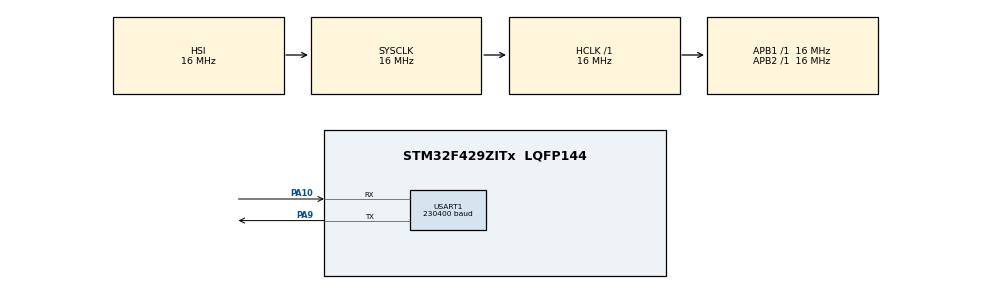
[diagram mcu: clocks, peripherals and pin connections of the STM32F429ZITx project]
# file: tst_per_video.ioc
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Mcu.Family=STM32F4
Mcu.Name=STM32F429ZITx
Mcu.Package=LQFP144
NVIC.PriorityGroup=NVIC_PRIORITYGROUP_4
NVIC.TIM1_UP_TIM10_IRQn=true\:0\:0\:false\:false\:true\:false\:true
NVIC.TimeBase=TIM1_UP_TIM10_IRQn
NVIC.TimeBaseIP=TIM1
PA10.Mode=Asynchronous
PA10.Signal=USART1_RX
PA13.Mode=Serial_Wire
PA13.Signal=SYS_JTMS-SWDIO
PA14.Mode=Serial_Wire
PA14.Signal=SYS_JTCK-SWCLK
PA9.Mode=Asynchronous
PA9.Signal=USART1_TX
PH0/OSC_IN.Mode=HSE-External-Oscillator
PH0/OSC_IN.Signal=RCC_OSC_IN
PH1/OSC_OUT.Mode=HSE-External-Oscillator
PH1/OSC_OUT.Signal=RCC_OSC_OUT
ProjectManager.HeapSize=0x200
ProjectManager.StackSize=0x400
ProjectManager.TargetToolchain=STM32CubeIDE
RCC.AHBFreq_Value=16000000
RCC.APB1Freq_Value=16000000
RCC.APB2Freq_Value=16000000
RCC.CortexFreq_Value=16000000
RCC.HSE_VALUE=25000000
RCC.HSI_VALUE=16000000
RCC.LSE_VALUE=32768
RCC.SYSCLKFreq_VALUE=16000000
RCC.VCOOutputFreq_Value=192000000
USART1.BaudRate=230400
USART1.VirtualMode=VM_ASYNC
VP_SYS_VS_tim1.Mode=TIM1
board=custom

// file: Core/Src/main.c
/* USER CODE BEGIN Header */
/**
 ******************************************************************************
 * @file           : main.c
 * @brief          : Main program body
 ******************************************************************************
 * @attention
 *
 * <h2><center>&copy; Copyright (c) 2020 STMicroelectronics.
 * All rights reserved.</center></h2>
 *
 * This software component is licensed by ST under BSD 3-Clause license,
 * the "License"; You may not use this file except in compliance with the
 * License. You may obtain a copy of the License at:
 *                        opensource.org/licenses/BSD-3-Clause
 *
 ******************************************************************************
 */
/* USER CODE END Header */

#define ARM_MATH_CM4

#include "main.h"
#include "arm_math.h"
#include "coefficients.h"

/* USER CODE BEGIN PD */
#define BUFFERSIZE	320
#define FILTERORDER 256
/* USER CODE END PD */

UART_HandleTypeDef huart1;

/* USER CODE BEGIN PV */
uint8_t txBuffer[BUFFERSIZE];

float32_t f_tempBuffer[BUFFERSIZE];
float32_t f_tempBuffer_out[BUFFERSIZE];

float32_t f_states[FILTERORDER];

q15_t temp_q15_Buffer[BUFFERSIZE];

typedef union{
	int16_t smp;
	uint8_t bytes[2];
} sample;

sample rxBuffer[BUFFERSIZE]; //Buffer de muestras

arm_fir_instance_f32 fir_0;
/* USER CODE END PV */

void SystemClock_Config(void);
static void MX_GPIO_Init(void);
static void MX_USART1_UART_Init(void);

int main(void)
{
	/* USER CODE BEGIN 1 */
	uint8_t data[]="1111";
	uint8_t rxdata[2];
	uint8_t txdata[2];

	int i;

	float32_t * currentCoef = left[0];

	arm_fir_init_f32(&fir_0, 256, currentCoef, f_states, BUFFERSIZE);
	/* USER CODE END 1 */

	/* MCU Configuration--------------------------------------------------------*/

	/* Reset of all peripherals, Initializes the Flash interface and the Systick. */
	HAL_Init();

	/* Configure the system clock */
	SystemClock_Config();

	/* Initialize all configured peripherals */
	MX_GPIO_Init();
	MX_USART1_UART_Init();

	/* Infinite loop */
	while (1)
	{

		/* USER CODE BEGIN 3 */
		HAL_UART_Receive(&huart1, rxBuffer->bytes, BUFFERSIZE*2, 10000);

		// Type changing
//		for(i=0;i<BUFFERSIZE;i++) {
//			temp_q15_Buffer[i*2+1]=(uint8_t)rxBuffer[i]&0xFF;
//			temp_q15_Buffer[i*2]=(uint8_t)rxBuffer[i]>>8;
//		}

		for (i = 0; i < BUFFERSIZE; i++) {
			f_tempBuffer[i] = (float32_t) rxBuffer[i].smp / 32768;
		}

		for (i = 0; i < 37; i++) {
			currentCoef = left[i];
//			arm_fir_f32(&fir_0, f_tempBuffer, f_tempBuffer_out, BUFFERSIZE);
		}

//		arm_q15_to_float(temp_q15_Buffer, f_tempBuffer, BUFFERSIZE);

		// Copy the data to the transmisor buffer
//		for (i = 0; i < 2; i++) {
//			txdata[i]=rxdata[i];
//		}

		i=0;

//		HAL_UART_Transmit(&huart1, txdata, 5, 1000);

	}
	/* USER CODE END 3 */
}

void SystemClock_Config(void)
{
	RCC_OscInitTypeDef RCC_OscInitStruct = {0};
	RCC_ClkInitTypeDef RCC_ClkInitStruct = {0};

	/** Configure the main internal regulator output voltage
	 */
	__HAL_RCC_PWR_CLK_ENABLE();
	__HAL_PWR_VOLTAGESCALING_CONFIG(PWR_REGULATOR_VOLTAGE_SCALE3);
	/** Initializes the CPU, AHB and APB busses clocks
	 */
	RCC_OscInitStruct.OscillatorType = RCC_OSCILLATORTYPE_HSI;
	RCC_OscInitStruct.HSIState = RCC_HSI_ON;
	RCC_OscInitStruct.HSICalibrationValue = RCC_HSICALIBRATION_DEFAULT;
	RCC_OscInitStruct.PLL.PLLState = RCC_PLL_NONE;
	if (HAL_RCC_OscConfig(&RCC_OscInitStruct) != HAL_OK)
	{
		Error_Handler();
	}
	/** Initializes the CPU, AHB and APB busses clocks
	 */
	RCC_ClkInitStruct.ClockType = RCC_CLOCKTYPE_HCLK|RCC_CLOCKTYPE_SYSCLK
			|RCC_CLOCKTYPE_PCLK1|RCC_CLOCKTYPE_PCLK2;
	RCC_ClkInitStruct.SYSCLKSource = RCC_SYSCLKSOURCE_HSI;
	RCC_ClkInitStruct.AHBCLKDivider = RCC_SYSCLK_DIV1;
	RCC_ClkInitStruct.APB1CLKDivider = RCC_HCLK_DIV1;
	RCC_ClkInitStruct.APB2CLKDivider = RCC_HCLK_DIV1;

	if (HAL_RCC_ClockConfig(&RCC_ClkInitStruct, FLASH_LATENCY_0) != HAL_OK)
	{
		Error_Handler();
	}
}

static void MX_USART1_UART_Init(void)
{

	huart1.Instance = USART1;
	huart1.Init.BaudRate = 230400;
	huart1.Init.WordLength = UART_WORDLENGTH_8B;
	huart1.Init.StopBits = UART_STOPBITS_1;
	huart1.Init.Parity = UART_PARITY_NONE;
	huart1.Init.Mode = UART_MODE_TX_RX;
	huart1.Init.HwFlowCtl = UART_HWCONTROL_NONE;
	huart1.Init.OverSampling = UART_OVERSAMPLING_16;
	if (HAL_UART_Init(&huart1) != HAL_OK)
	{
		Error_Handler();
	}

}

static void MX_GPIO_Init(void)
{

	/* GPIO Ports Clock Enable */
	__HAL_RCC_GPIOH_CLK_ENABLE();
	__HAL_RCC_GPIOA_CLK_ENABLE();

}

void HAL_TIM_PeriodElapsedCallback(TIM_HandleTypeDef *htim)
{
	if (htim->Instance == TIM1) {
		HAL_IncTick();
	}
}

void Error_Handler(void)
{
}

/************************ (C) COPYRIGHT STMicroelectronics *****END OF FILE****/
